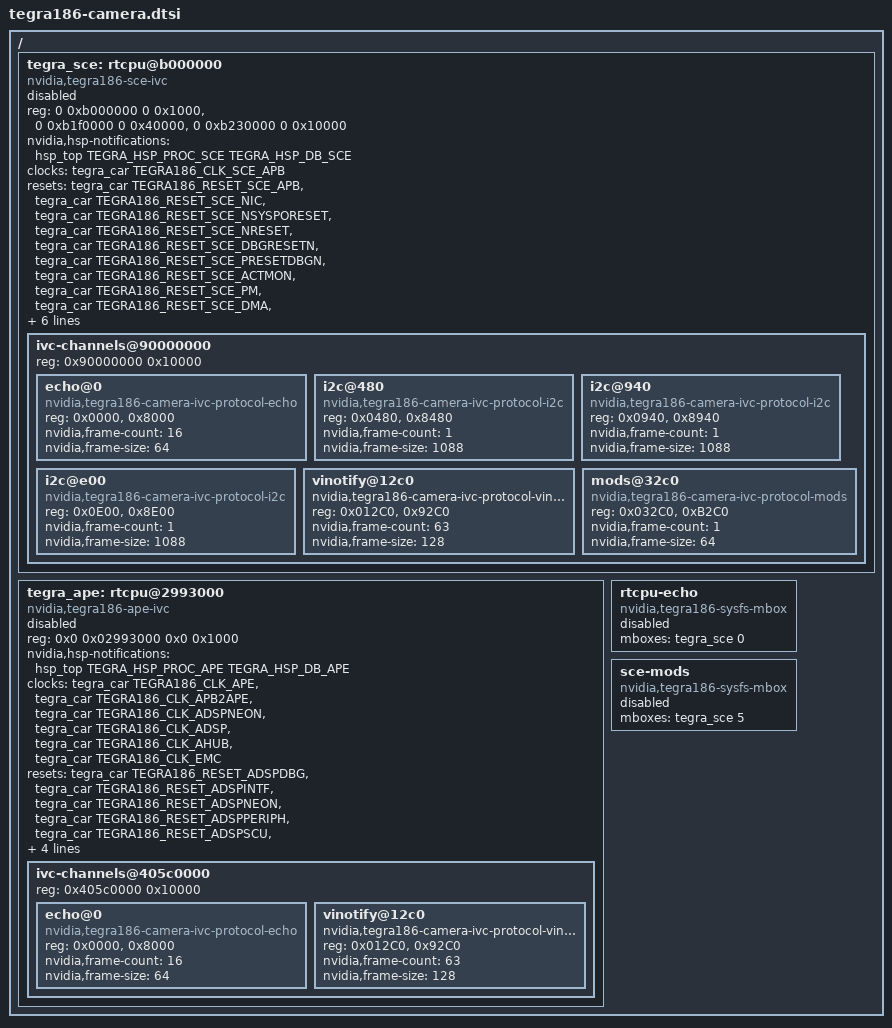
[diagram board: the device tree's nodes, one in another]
/*
 * tegra186-camera.dtsi: Camera RTCPU DTSI file.
 *
 * Copyright (c) 2015-2016 NVIDIA Corporation.  All rights reserved.
 *
 * This program is free software; you can redistribute it and/or modify
 * it under the terms of the GNU General Public License as published by
 * the Free Software Foundation; version 2 of the License.
 *
 * This program is distributed in the hope that it will be useful, but WITHOUT
 * ANY WARRANTY; without even the implied warranty of MERCHANTABILITY or
 * FITNESS FOR A PARTICULAR PURPOSE.  See the GNU General Public License for
 * more details.
 *
 * You should have received a copy of the GNU General Public License along
 * with this program; if not, write to the Free Software Foundation, Inc.,
 * 51 Franklin Street, Fifth Floor, Boston, MA  02110-1301, USA.
 *
 */

/ {
	tegra_sce: rtcpu@b000000 {
		compatible = "nvidia,tegra186-sce-ivc";
		status = "disabled";

		reg =	<0 0xb000000 0 0x1000>,	  /* SCE EVP (SCE_ATCM_EVP) */
			<0 0xb1f0000 0 0x40000>,  /* SCE PM */
			<0 0xb230000 0 0x10000>;  /* APS_FRSC (SCE_CFG) */

		nvidia,hsp-notifications = <&hsp_top
					TEGRA_HSP_PROC_SCE
					TEGRA_HSP_DB_SCE>;
		#stream-id-cells = <1>;

		#mbox-cells = <1>;			 /* This is mbox controller device */

		clocks = <&tegra_car TEGRA186_CLK_SCE_APB>;
		clock-names = "sce-apb";
		resets =
			<&tegra_car TEGRA186_RESET_SCE_APB>,
			<&tegra_car TEGRA186_RESET_SCE_NIC>,
			<&tegra_car TEGRA186_RESET_SCE_NSYSPORESET>,
			<&tegra_car TEGRA186_RESET_SCE_NRESET>,
			<&tegra_car TEGRA186_RESET_SCE_DBGRESETN>,
			<&tegra_car TEGRA186_RESET_SCE_PRESETDBGN>,
			<&tegra_car TEGRA186_RESET_SCE_ACTMON>,
			<&tegra_car TEGRA186_RESET_SCE_PM>,
			<&tegra_car TEGRA186_RESET_SCE_DMA>,
			<&tegra_car TEGRA186_RESET_SCE_HSP>,
			<&tegra_car TEGRA186_RESET_TSCTNSCE>,
			<&tegra_car TEGRA186_RESET_SCE_TKE>,
			<&tegra_car TEGRA186_RESET_SCE_GTE>,
			<&tegra_car TEGRA186_RESET_SCE_CFG>;
		reset-names =
			"sce-apb",
			"sce-nic",
			"sce-nsysporeset",
			"sce-nreset",
			"sce-dbgresetn",
			"sce-presetdbgn",
			"sce-actmon",
			"sce-pm",
			"sce-dma",
			"sce-hsp",
			"tsctnsce",
			"sce-tke",
			"sce-gte",
			"sce-cfg";

		nvidia,ast = <&sce_ast0>, <&sce_ast1>;

		#address-cells = <1>;
		#size-cells = <1>;

		ivc-channels@90000000  {
			reg = <0x90000000 0x10000>;

			#address-cells = <1>;
			#size-cells = <0>;

			echo@0 {
				compatible = "nvidia,tegra186-camera-ivc-protocol-echo";
				reg = <0x0000>, <0x8000>;
				reg-names = "rx", "tx";
				nvidia,frame-count = <16>;
				nvidia,frame-size = <64>;
			};
			i2c@480 {
				compatible = "nvidia,tegra186-camera-ivc-protocol-i2c";
				reg = <0x0480>, <0x8480>;
				reg-names = "rx", "tx";
				nvidia,frame-count = <1>;
				nvidia,frame-size = <1088>;
			};
			i2c@940 {
				compatible = "nvidia,tegra186-camera-ivc-protocol-i2c";
				reg = <0x0940>, <0x8940>;
				reg-names = "rx", "tx";
				nvidia,frame-count = <1>;
				nvidia,frame-size = <1088>;
			};
			i2c@e00 {
				compatible = "nvidia,tegra186-camera-ivc-protocol-i2c";
				reg = <0x0E00>, <0x8E00>;
				reg-names = "rx", "tx";
				nvidia,frame-count = <1>;
				nvidia,frame-size = <1088>;
			};
			vinotify@12c0 {
				compatible = "nvidia,tegra186-camera-ivc-protocol-vinotify";
				reg = <0x012C0>, <0x92C0>;
				reg-names = "rx", "tx";
				nvidia,frame-count = <63>;
				nvidia,frame-size = <128>;
			};
			mods@32c0 {
				compatible = "nvidia,tegra186-camera-ivc-protocol-mods";
				reg = <0x032C0>, <0xB2C0>;
				reg-names = "rx", "tx";
				nvidia,frame-count = <1>;
				nvidia,frame-size = <64>;
		       };
		};
	};

	tegra_ape: rtcpu@2993000 {
		compatible = "nvidia,tegra186-ape-ivc";
		status = "disabled";

		reg = <0x0 0x02993000 0x0 0x1000>; /* APE EVP */

		nvidia,hsp-notifications = <&hsp_top
					TEGRA_HSP_PROC_APE
					TEGRA_HSP_DB_APE>;
		#stream-id-cells = <1>;

		#mbox-cells = <1>;

		clocks =
			<&tegra_car TEGRA186_CLK_APE>,
			<&tegra_car TEGRA186_CLK_APB2APE>,
			<&tegra_car TEGRA186_CLK_ADSPNEON>,
			<&tegra_car TEGRA186_CLK_ADSP>,
			<&tegra_car TEGRA186_CLK_AHUB>,
			<&tegra_car TEGRA186_CLK_EMC>;
		clock-names =
			"ape",
			"apb2ape",
			"adspneon",
			"adsp",
			"ahub",
			"adsp.emc";
		resets =
			<&tegra_car TEGRA186_RESET_ADSPDBG>,
			<&tegra_car TEGRA186_RESET_ADSPINTF>,
			<&tegra_car TEGRA186_RESET_ADSPNEON>,
			<&tegra_car TEGRA186_RESET_ADSPPERIPH>,
			<&tegra_car TEGRA186_RESET_ADSPSCU>,
			<&tegra_car TEGRA186_RESET_ADSPWDT>,
			<&tegra_car TEGRA186_RESET_APE>,
			<&tegra_car TEGRA186_RESET_ADSP>;
		reset-names =
				"adspdbg",
				"adspintf",
				"adspneon",
				"adspperiph",
				"adspscu",
				"adspwdt",
				"ape",
				"adsp";

		nvidia,ast = <&ape_ast0>, <&ape_ast1>;

		#address-cells = <1>;
		#size-cells = <1>;

		ivc-channels@405c0000 {
			reg = <0x405c0000 0x10000>;

			#address-cells = <1>;
			#size-cells = <0>;

			echo@0 {
				compatible = "nvidia,tegra186-camera-ivc-protocol-echo";
				reg = <0x0000>, <0x8000>;
				reg-names = "rx", "tx";
				nvidia,frame-count = <16>;
				nvidia,frame-size = <64>;
			};

			vinotify@12c0 {
				compatible = "nvidia,tegra186-camera-ivc-protocol-vinotify";
				reg = <0x012C0>, <0x92C0>;
				reg-names = "rx", "tx";
				nvidia,frame-count = <63>;
				nvidia,frame-size = <128>;
			};
		};
	};

	rtcpu-echo {
		compatible = "nvidia,tegra186-sysfs-mbox";
		status = "disabled";
		mboxes = <&tegra_sce 0>;
	};

	sce-mods {
		compatible = "nvidia,tegra186-sysfs-mbox";
		status = "disabled";
		mboxes = <&tegra_sce 5>;
	};
};
